# STM32WB55xx register map
File version: 1.0
Registers are 32-bit, read-write, reset 0x0 unless marked. A register's access mark holds for its fields unless they carry their own. Offsets are from the block's base; [hi:lo] are bit positions; {n}, {i} and the like mark numbered series.

## GPIOA — General Purpose I/O
Base 0x48000000
Same registers: GPIOB 0x48000400, GPIOC 0x48000800, GPIOD 0x48000C00, GPIOE 0x48001000, GPIOH 0x48001C00
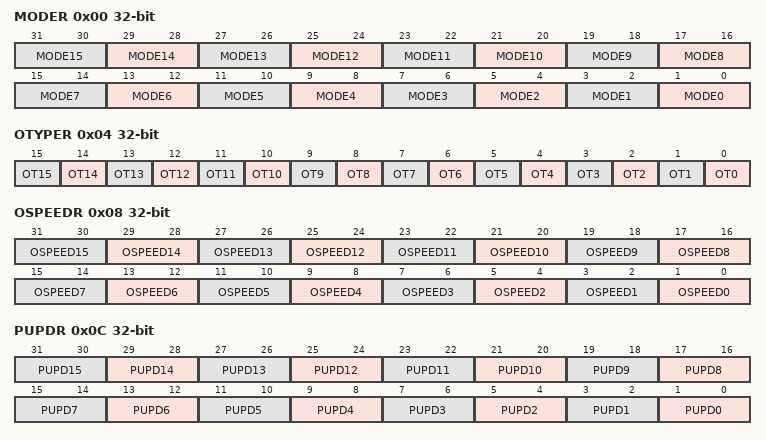
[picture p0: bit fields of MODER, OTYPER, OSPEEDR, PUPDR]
0x00 MODER — GPIO port mode register
  [2n+1:2n] MODE{n} (n=0..15)
0x04 OTYPER — GPIO port output type register
  [n] OT{n} (n=0..15)
0x08 OSPEEDR — GPIO port output speed register
  [2n+1:2n] OSPEED{n} (n=0..15)
0x0C PUPDR — GPIO port pull-up/pull-down register
  [2n+1:2n] PUPD{n} (n=0..15)
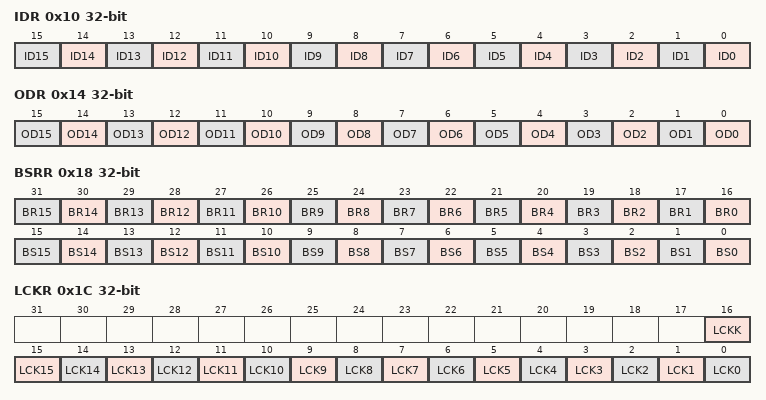
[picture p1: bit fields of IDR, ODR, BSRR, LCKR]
0x10 IDR — GPIO port input data register
  [n] ID{n} (n=0..15)
0x14 ODR — GPIO port output data register
  [n] OD{n} (n=0..15)
0x18 BSRR — GPIO port bit set/reset register
  [n+16] BR{n} (n=0..15), [n] BS{n} (n=0..15)
0x1C LCKR — GPIO port configuration lock register
  [16] LCKK, [n] LCK{n} (n=0..15)
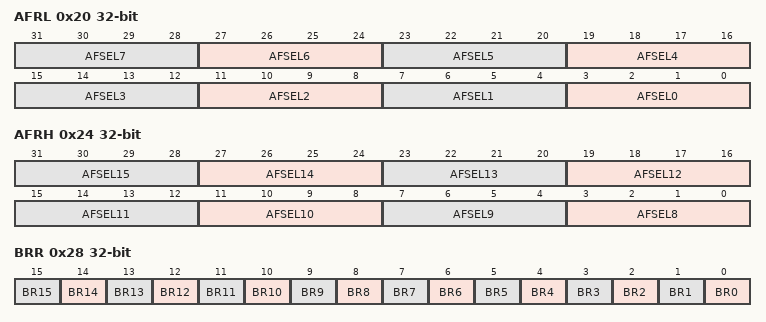
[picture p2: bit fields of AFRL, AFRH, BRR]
0x20 AFRL — GPIO alternate function registers
  [4n+3:4n] AFSEL{n} (n=0..7)
0x24 AFRH — GPIO alternate function registers
  [4n-29:4n-32] AFSEL{n} (n=8..15)
0x28 BRR — GPIO Bit Reset register
  [n] BR{n} (n=0..15)

## AES1 — AES hardware accelerator
Base 0x50060000
Same registers: AES2 0x58001800
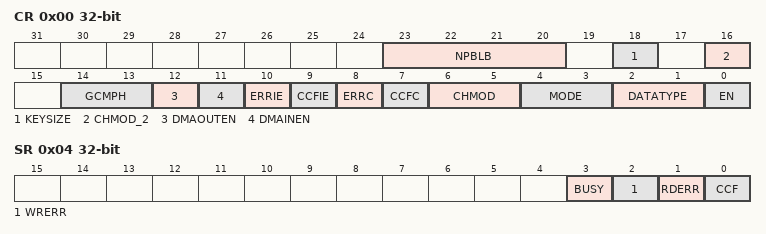
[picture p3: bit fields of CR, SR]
0x00 CR — AES control register
  [23:20] NPBLB — Number of padding bytes in last payload block
  [18] KEYSIZE — Key size selection
  [16] CHMOD_2 — AES Chaining Mode
  [14:13] GCMPH — GCM Phase
  [12] DMAOUTEN — Enable data output phase DMA management
  [11] DMAINEN — Enable data input phase DMA management
  [10] ERRIE — Error Interrupt Enable
  [9] CCFIE — Computation Complete Flag Interrupt Enable
  [8] ERRC — Error Clear
  [7] CCFC — Computation Complete Flag Clear
  [6:5] CHMOD — AES Chaining Mode
  [4:3] MODE — AES Mode Of Operation
  [2:1] DATATYPE — Data type selection
  [0] EN — AES Enable
0x04 SR — AES status register
  [3] BUSY — Busy Flag
  [2] WRERR — Write Error Flag
  [1] RDERR — Read Error Flag
  [0] CCF — Computation Complete Flag
0x08 DINR — AES data input register
  [31:0] DINR — AES Data Input Register
0x0C DOUTR — AES data output register
  [31:0] DOUTR — AES Data Output Register
{0x10+4i} KEYR{i} (i=0..3) — AES key register {i}
  [31:0] KEYR{i} — AES Key Register {i}
{0x20+4i} IVR{i} (i=0..3) — AES initialization vector register {i}
  [31:0] IVR{i} — AES Initialization Vector Register {i}
{0x20+4i} KEYR{i} (i=4..7) — AES key register {i}
  [31:0] KEYR{i} — AES Key Register {i}
{0x40+4i} SUSP{i}R (i=0..7) — AES Suspend register {i}
  [31:0] SUSP{i}R — AES Suspend registers {i}

## EXTI — Async Interrupts and Events Controller
Base 0x58000800
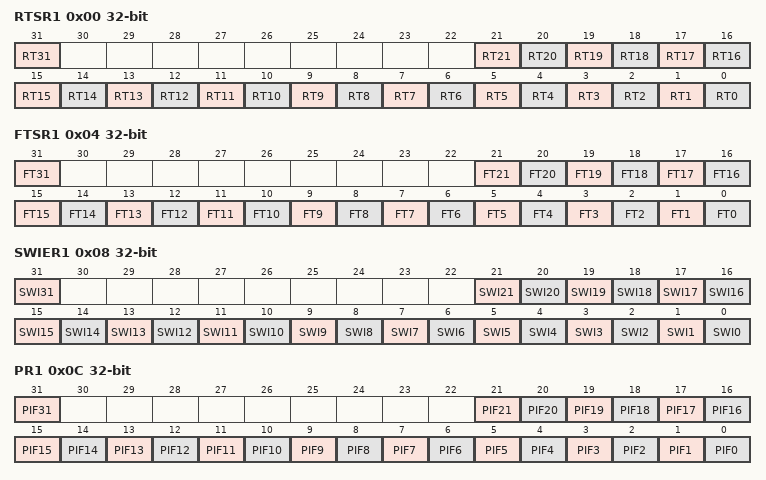
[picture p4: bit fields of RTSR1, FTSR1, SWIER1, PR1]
0x00 RTSR1 — EXTI rising trigger selection register [31:0]
  [31] RT31 — Rising trigger event configuration bit of line 31
  [n] RT{n} (n=0..21) — Rising trigger event configuration bit of line {n}
0x04 FTSR1 — EXTI falling trigger selection register [31:0]
  [31] FT31 — Falling trigger event configuration bit of line 31
  [n] FT{n} (n=0..21) — Falling trigger event configuration bit of line {n}
0x08 SWIER1 — EXTI software interrupt event register [31:0]
  [31] SWI31 — Software Interrupt on line 31
  [n] SWI{n} (n=0..21) — Software Interrupt on line {n}
0x0C PR1 — EXTI pending register [31:0]
  [31] PIF31 — Pending bit for line 31
  [n] PIF{n} (n=0..21) — Pending bit for line {n}
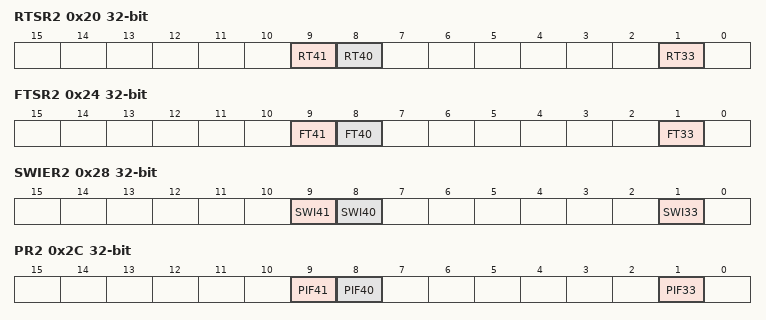
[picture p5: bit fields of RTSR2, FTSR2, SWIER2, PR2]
0x20 RTSR2 — EXTI rising trigger selection register [31:0]
  [9] RT41 — Rising trigger event configuration bit of line 41
  [8] RT40 — Rising trigger event configuration bit of line 40
  [1] RT33 — Rising trigger event configuration bit of line 33
0x24 FTSR2 — EXTI falling trigger selection register [31:0]
  [9] FT41 — Falling trigger event configuration bit of line 41
  [8] FT40 — Falling trigger event configuration bit of line 40
  [1] FT33 — Falling trigger event configuration bit of line 33
0x28 SWIER2 — EXTI software interrupt event register [31:0]
  [9] SWI41 — Software Interrupt on line 41
  [8] SWI40 — Software Interrupt on line 40
  [1] SWI33 — Software Interrupt on line 33
0x2C PR2 — EXTI pending register [31:0]
  [9] PIF41 — Pending bit for line 41
  [8] PIF40 — Pending bit for line 40
  [1] PIF33 — Pending bit for line 33
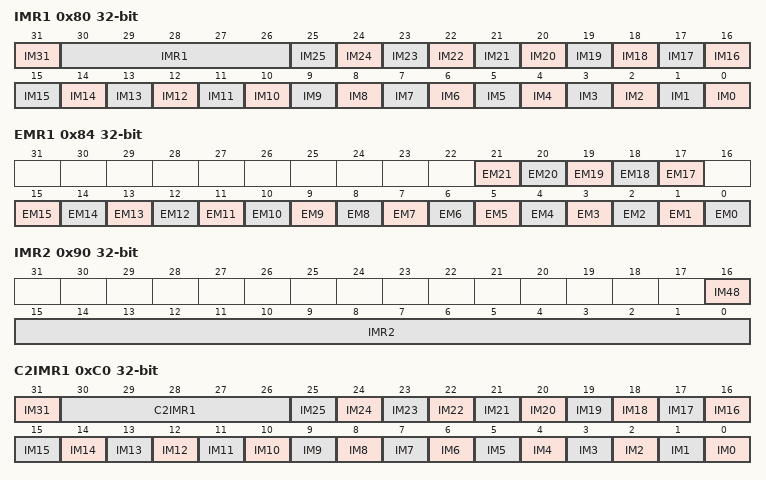
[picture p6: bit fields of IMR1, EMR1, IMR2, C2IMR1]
0x80 IMR1 — EXTI wakeup with interrupt mask register for cpu1 [31:0]
  [31] IM31 — CPU1 Interrupt Mask on line 31
  [30:26] IMR1
  [n] IM{n} (n=0..25) — CPU1 Interrupt Mask on line {n}
0x84 EMR1 — EXTI wakeup with event mask register for cpu1 [31:0]
  [n] EM{n} (n=17..21) — CPU1 Event Mask on line {n}
  [n] EM{n} (n=0..15) — CPU1 Event Mask on line {n}
0x90 IMR2 — EXTI wakeup with interrupt mask register for cpu1 [31:0]
  [16] IM48 — CPU1 Interrupt Mask on line 48
  [15:0] IMR2
0x94 EMR2 — EXTI wakeup with event mask register for cpu1 [31:0]
  [9:8] EMR2
0xC0 C2IMR1 — EXTI wakeup with interrupt mask register for cpu2 [31:0]
  [31] IM31 — CPU2 Interrupt Mask on line 31
  [30:26] C2IMR1
  [n] IM{n} (n=0..25) — CPU2 Interrupt Mask on line {n}
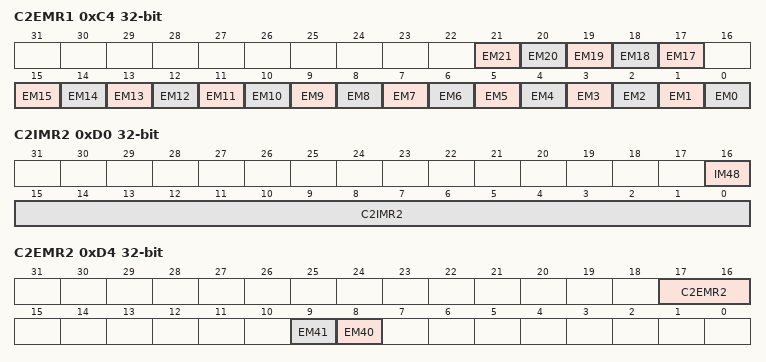
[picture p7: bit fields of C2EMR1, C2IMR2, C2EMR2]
0xC4 C2EMR1 — EXTI wakeup with event mask register for cpu2 [31:0]
  [n] EM{n} (n=17..21) — CPU2 Event Mask on line {n}
  [n] EM{n} (n=0..15) — CPU2 Event Mask on line {n}
0xD0 C2IMR2 — EXTI wakeup with interrupt mask register for cpu2 [31:0]
  [16] IM48 — CPU2 Interrupt Mask on line 48
  [15:0] C2IMR2
0xD4 C2EMR2 — EXTI wakeup with event mask register for cpu2 [31:0]
  [17:16] C2EMR2
  [9] EM41 — CPU2 Event Mask on line 41
  [8] EM40 — CPU2 Event Mask on line 40
